# STM32WBA52 register map
File version: 1.3
CPU: CM33 r0p1, little endian, MPU, FPU, 4 interrupt priority bits
Registers are 32-bit, read-write, reset 0x0 unless marked. A register's access mark holds for its fields unless they carry their own. Offsets are from the block's base; [hi:lo] are bit positions; {n}, {i} and the like mark numbered series.

## GPIOH — General-purpose I/Os
Base 0x42021C00
Same registers: SEC_GPIOH 0x52021C00
0x00 GPIOH_MODER reset 0xC000 — GPIO port H mode register
  [7:6] MODE3 — Port H configuration I/O pin 3 These bits are written by software to configure the I/O mode. Access can be protected by GPIOH SEC3.
    0=Input mode; 1=General purpose output mode; 2=Alternate function mode; 3=Analog mode (reset state)
0x04 GPIOH_OTYPER — GPIO port H output type register
  [3] OT3 — Port H configuration I/O pin 3 This bit is written by software to configure the I/O output type. Access can be protected by GPIOH SEC3.
    0=Output push-pull (reset state); 1=Output open-drain
0x08 GPIOH_OSPEEDR — GPIO port H output speed register
  [7:6] OSPEED3 — Port H configuration I/O pin 3 These bits are written by software to configure the I/O output speed. Access can be protected by GPIOH SEC3. Note: Refer to the device datasheet for the frequency specifications and the power supply and load conditions for each speed.
    0=Low speed; 1=Medium speed; 2=High speed
0x0C GPIOH_PUPDR — GPIO port H pull-up/pull-down register
  [7:6] PUPD3 — Port H configuration I/O pin 3 These bits are written by software to configure the I/O pull-up or pull-down Access can be protected by GPIOH SEC3.
    0=No pull-up, pull-down; 1=Pull-up; 2=Pull-down
0x10 GPIOH_IDR ro (reset mask 0xFFFF0000) — GPIO port H input data register
  [3] ID3 — Port H input data I/O pin 3 This bit is read-only. It contain the input value of the corresponding I/O port. Access can be protected by GPIOH SEC3.
0x14 GPIOH_ODR — GPIO port H output data register
  [3] OD3 — Port H output data I/O pin 3 This bits can be read and written by software. Access can be protected by GPIOH SEC3. Note: For atomic bit set/reset, the OD bit can be individually set and/or reset by writing to the GPIOH_BSRR or GPIOH_BRR registers.
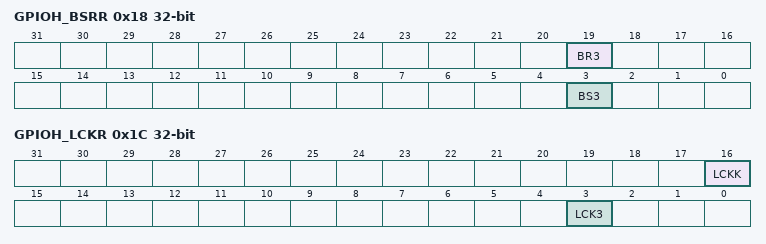
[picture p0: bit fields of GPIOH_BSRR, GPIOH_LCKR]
0x18 GPIOH_BSRR wo — GPIO port H bit set/reset register
  [19] BR3 — Port H reset I/O pin 3 This bit is write-only. A read to this bit returns the value 0. Access can be protected by GPIOH SEC3. Note: If both BS3 and BR3 are set, BS3 has priority.
    0=No action on the corresponding OD3 bit; 1=Resets the corresponding OD3 bit
  [3] BS3 — Port H set I/O pin 3 This bit is write-only. A read to this bit returns the value 0. Access can be protected by GPIOH SEC3.
    0=No action on the corresponding OD3 bit; 1=Sets the corresponding OD3 bit
0x1C GPIOH_LCKR — GPIO port H configuration lock register
  [16] LCKK — Lock key This bit can be read any time. It can only be modified using the lock key write sequence. Access is protected by GPIOH SEC3. - LOCK key write sequence: WR LCKR[16] = 1 + LCKR[3] WR LCKR[16] = 0 + LCKR[3] WR LCKR[16] = 1 + LCKR[3] - LOCK key read RD LCKR[16] = 1 (this read operation is optional but it confirms that the lock is active) Note: During the LOCK key write sequence, the value of LCK3 must not change. Note: Any error in the lock sequence aborts the LOCK. Note: After the first LOCK sequence on any bit of the port, any read access on the LCKK bit returns 1 until the next MCU reset or peripheral reset.
    0=Port configuration lock key not active; 1=Port configuration lock key active. The GPIOH_LCKR register is locked until the next MCU reset or peripheral reset.
  [3] LCK3 — Port H lock I/O pin 3 This bit is read/write but can only be written when the LCKK bit is 0 Access can be protected by GPIOH SEC3.
    0=Port configuration not locked; 1=Port configuration locked
0x20 GPIOH_AFRL — GPIO port H alternate function low register
  [15:12] AFSEL3 — Alternate function selection for port H I/O pin 3 These bits are written by software to configure alternate function I/Os. Access can be protected by GPIOH SEC3.
    {v}=AF{v} (v=0..15)
0x28 GPIOH_BRR wo — GPIO port H bit reset register
  [3] BR3 — Port H reset I/O pin 3 This bit is write-only. A read to this bit returns the value 0. Access can be protected by GPIOH SEC3.
    0=No action on the corresponding OD3 bit; 1=Reset the corresponding OD3 bit
0x30 GPIOH_SECCFGR wo reset 0xFFFF — GPIO port H secure configuration register
  [3] SEC3 — I/O pin of port H secure bit enable 3 This bit is written by software to enabled the security I/O port pin.
    0=The I/O pin is non-secure; 1=The I/O pin is secure. Refer to Table 112 for all corresponding secured bits.
